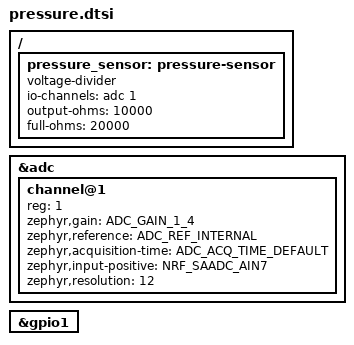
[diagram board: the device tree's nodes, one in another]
&adc {
	status = "okay";
	#address-cells = <1>;
	#size-cells = <0>;

	channel@1 {
		reg = <1>;
		zephyr,gain = "ADC_GAIN_1_4";
		zephyr,reference = "ADC_REF_INTERNAL";
		zephyr,acquisition-time = <ADC_ACQ_TIME_DEFAULT>;
		zephyr,input-positive = <NRF_SAADC_AIN7>; /* P1.14 */
		zephyr,resolution = <12>;
	};
};

/ {
	pressure_sensor: pressure-sensor {
		compatible = "voltage-divider";
		status = "okay";
		io-channels = <&adc 1>;
		output-ohms = <10000>;
		full-ohms = <20000>;
	};
};

&gpio1 {
	status = "okay";
};
